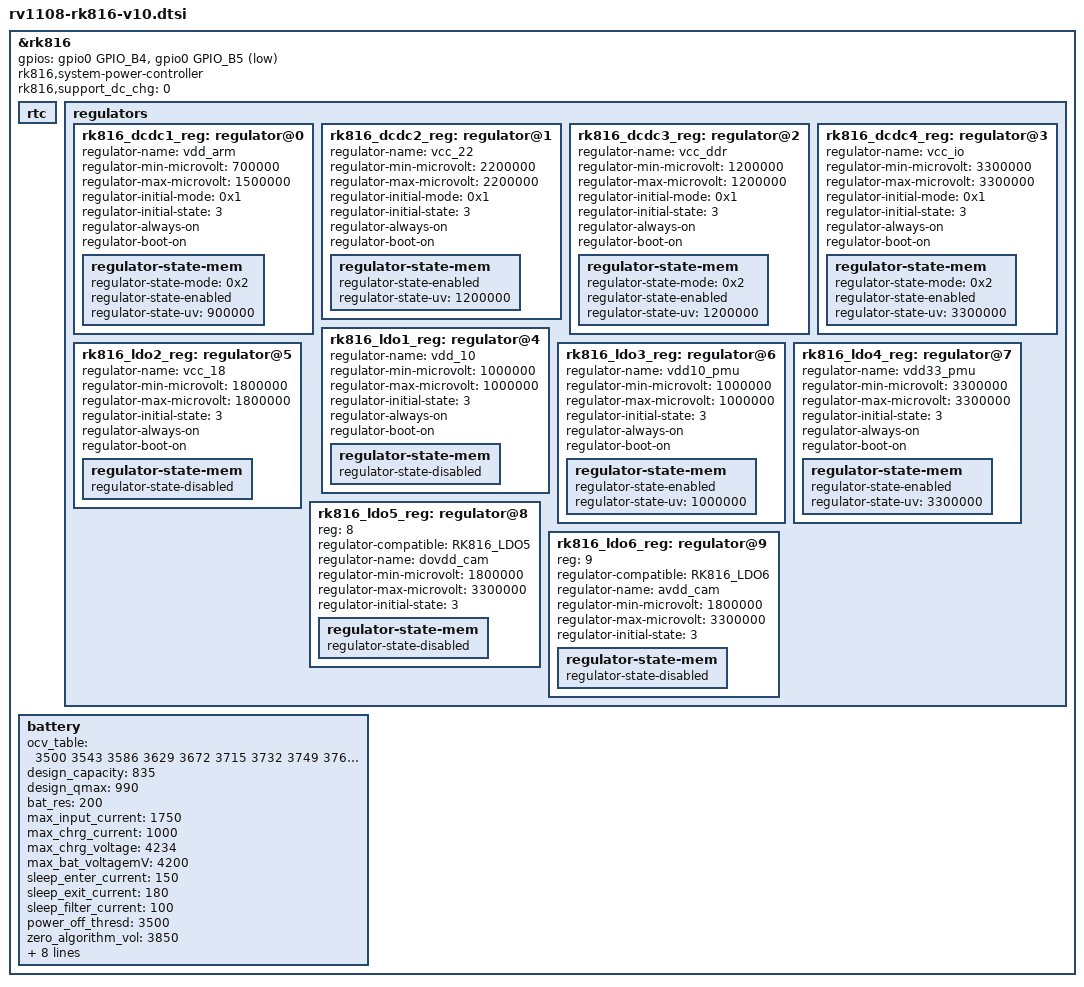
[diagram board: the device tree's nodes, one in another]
#include "rk816.dtsi"
&rk816{
	gpios = <&gpio0 GPIO_B4 GPIO_ACTIVE_HIGH>, <&gpio0 GPIO_B5 GPIO_ACTIVE_LOW>;
	rk816,system-power-controller;
	rk816,support_dc_chg = <0>;/*1: dc chg; 0:usb chg*/

	rtc {
		status = "okay";
	};

	regulators {
		/* override the ldo5, ldo6 */
		/delete-node/ regulator@8;
		/delete-node/ regulator@9;

		rk816_dcdc1_reg: regulator@0 {
			regulator-name= "vdd_arm";
			regulator-min-microvolt = <700000>;
			regulator-max-microvolt = <1500000>;
			regulator-initial-mode = <0x1>;
			regulator-initial-state = <3>;
			regulator-always-on;
			regulator-boot-on;
			regulator-state-mem {
				regulator-state-mode = <0x2>;
				regulator-state-enabled;
				regulator-state-uv = <900000>;
			};
		};

		rk816_dcdc2_reg: regulator@1 {
			regulator-name= "vcc_22";
			regulator-min-microvolt = <2200000>;
			regulator-max-microvolt = <2200000>;
			regulator-initial-mode = <0x1>;
			regulator-initial-state = <3>;
			regulator-always-on;
			regulator-boot-on;
			regulator-state-mem {
				regulator-state-enabled;
				regulator-state-uv = <1200000>;
			};
		};

		rk816_dcdc3_reg: regulator@2 {
			regulator-name= "vcc_ddr";
			regulator-min-microvolt = <1200000>;
			regulator-max-microvolt = <1200000>;
			regulator-initial-mode = <0x1>;
			regulator-initial-state = <3>;
			regulator-always-on;
			regulator-boot-on;
			regulator-state-mem {
				regulator-state-mode = <0x2>;
				regulator-state-enabled;
				regulator-state-uv = <1200000>;
			};
		};

		rk816_dcdc4_reg: regulator@3 {
			regulator-name= "vcc_io";
			regulator-min-microvolt = <3300000>;
			regulator-max-microvolt = <3300000>;
			regulator-initial-mode = <0x1>;
			regulator-initial-state = <3>;
			regulator-always-on;
			regulator-boot-on;
			regulator-state-mem {
				regulator-state-mode = <0x2>;
				regulator-state-enabled;
				regulator-state-uv = <3300000>;
			};
		};

		rk816_ldo1_reg: regulator@4 {
			regulator-name= "vdd_10";
			regulator-min-microvolt = <1000000>;
			regulator-max-microvolt = <1000000>;
			regulator-initial-state = <3>;
			regulator-always-on;
			regulator-boot-on;
			regulator-state-mem {
				regulator-state-disabled;
			};
		};

		rk816_ldo2_reg: regulator@5 {
			regulator-name= "vcc_18";
			regulator-min-microvolt = <1800000>;
			regulator-max-microvolt = <1800000>;
			regulator-initial-state = <3>;
			regulator-always-on;
			regulator-boot-on;
			regulator-state-mem {
				regulator-state-disabled;
			};
		};

		rk816_ldo3_reg: regulator@6 {
			regulator-name= "vdd10_pmu";
			regulator-min-microvolt = <1000000>;
			regulator-max-microvolt = <1000000>;
			regulator-initial-state = <3>;
			regulator-always-on;
			regulator-boot-on;
			regulator-state-mem {
				regulator-state-enabled;
				regulator-state-uv = <1000000>;
			};
		};

		rk816_ldo4_reg: regulator@7 {
			regulator-name= "vdd33_pmu";
			regulator-min-microvolt = <3300000>;
			regulator-max-microvolt = <3300000>;
			regulator-initial-state = <3>;
			regulator-always-on;
			regulator-boot-on;
			regulator-state-mem {
				regulator-state-enabled;
				regulator-state-uv = <3300000>;
			};
		};

		rk816_ldo5_reg: regulator@8 {
			reg = <8>;
			regulator-compatible = "RK816_LDO5";
			regulator-name= "dovdd_cam";
			regulator-min-microvolt = <1800000>;
			regulator-max-microvolt = <3300000>;
			regulator-initial-state = <3>;
			regulator-state-mem {
				regulator-state-disabled;
			};
		};

		rk816_ldo6_reg: regulator@9 {
			reg = <9>;
			regulator-compatible = "RK816_LDO6";
			regulator-name= "avdd_cam";
			regulator-min-microvolt = <1800000>;
			regulator-max-microvolt = <3300000>;
			regulator-initial-state = <3>;
			regulator-state-mem {
				regulator-state-disabled;
			};
		};
	};

	battery {
		ocv_table = <3500 3543 3586 3629 3672 3715 3732
			3749 3767 3784 3801 3827 3853 3878
			3904 3930 3954 3978 4002 4026 4050>;

		design_capacity = <835>;
		design_qmax = <990>;
		bat_res = <200>;
		max_input_current = <1750>;
		max_chrg_current = <1000>;
		max_chrg_voltage = <4234>;
		max_bat_voltagemV = <4200>;
		sleep_enter_current = <150>;
		sleep_exit_current = <180>;
		sleep_filter_current = <100>;
		power_off_thresd = <3500>;
		zero_algorithm_vol = <3850>;
		fb_temperature = <0>;
		sample_res = <50>;
		energy_mode = <0>;
		max_soc_offset = <60>;
		monitor_sec = <5>;
		virtual_power = <0>;
		power_dc2otg = <1>;
		dc_det_adc = <1>;
	};
};
